# f29h85x_hsm_fri_regs register map
Vendor: Texas Instruments
Peripheral module from a debugger description file (folder HSM).
Registers are 32-bit, read-only, no defined reset value unless marked. A register's access mark holds for its fields unless they carry their own. Offsets are as the file gives them; lines under a group give offsets from that group; [hi:lo] are bit positions; {n}, {i} and the like mark numbered series; 'fields as' and 'values as' point back to an identical list; <NAME> marks a mode.

## HSM_FRI — HSM FRI Registers
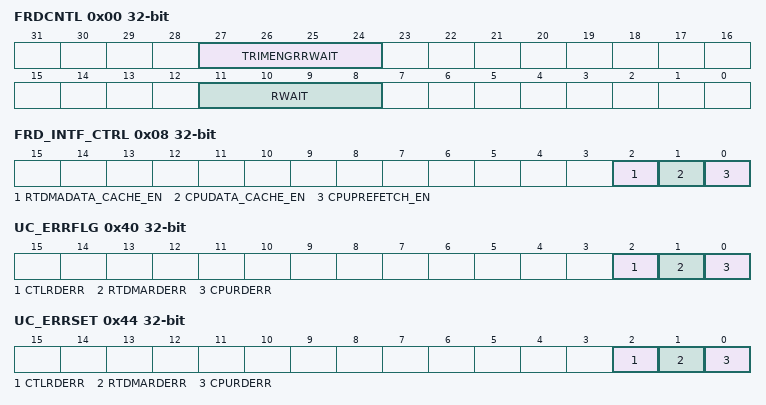
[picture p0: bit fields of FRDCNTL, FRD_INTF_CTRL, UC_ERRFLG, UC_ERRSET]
0x00 FRDCNTL access per field
  [27:24] TRIMENGRRWAIT rw, [11:8] RWAIT rw
0x04 FLCLKCTL access per field
  [3:0] KDIV rw
0x08 FRD_INTF_CTRL access per field
  [2] RTDMADATA_CACHE_EN rw, [1] CPUDATA_CACHE_EN rw, [0] CPUPREFETCH_EN rw
0x0C FLPROT access per field
  [0] FLWEPROT rw
{0x10+4i} RESERVED_1[{i}] (i=0..3)
0x20 ECC_ENABLE access per field
  [3:0] ENABLE rw
0x24 FECC_CTRL access per field
  [1:0] ECC_TEST_EN rw
{0x28+4i} RESERVED_2[{i}] (i=0..5)
0x40 UC_ERRFLG
  [2] CTLRDERR, [1] RTDMARDERR, [0] CPURDERR
0x44 UC_ERRSET access per field
  [2] CTLRDERR rw, [1] RTDMARDERR rw, [0] CPURDERR rw
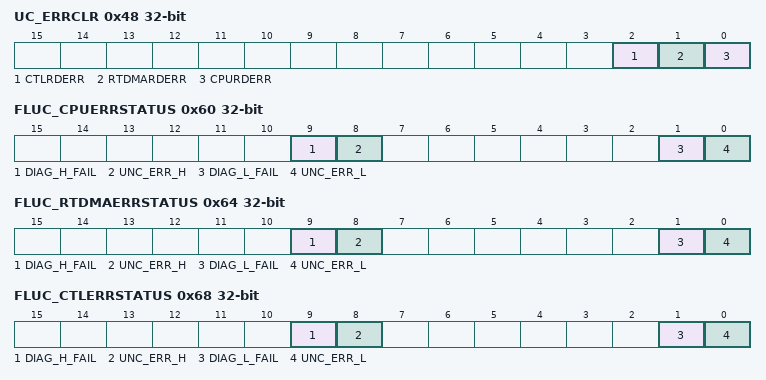
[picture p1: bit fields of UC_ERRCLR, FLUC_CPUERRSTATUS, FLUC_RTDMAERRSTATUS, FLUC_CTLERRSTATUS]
0x48 UC_ERRCLR access per field
  [2] CTLRDERR rw, [1] RTDMARDERR rw, [0] CPURDERR rw
0x4C UC_CPUREADDR
0x50 UC_RTDMAREADDR
0x54 UC_CTLREADDR
{0x58+4i} RESERVED_3[{i}] (i=0..1)
0x60 FLUC_CPUERRSTATUS
  [9] DIAG_H_FAIL, [8] UNC_ERR_H, [1] DIAG_L_FAIL, [0] UNC_ERR_L
0x64 FLUC_RTDMAERRSTATUS
  [9] DIAG_H_FAIL, [8] UNC_ERR_H, [1] DIAG_L_FAIL, [0] UNC_ERR_L
0x68 FLUC_CTLERRSTATUS
  [9] DIAG_H_FAIL, [8] UNC_ERR_H, [1] DIAG_L_FAIL, [0] UNC_ERR_L
{0x6C+4i} RESERVED_4[{i}] (i=0..4)
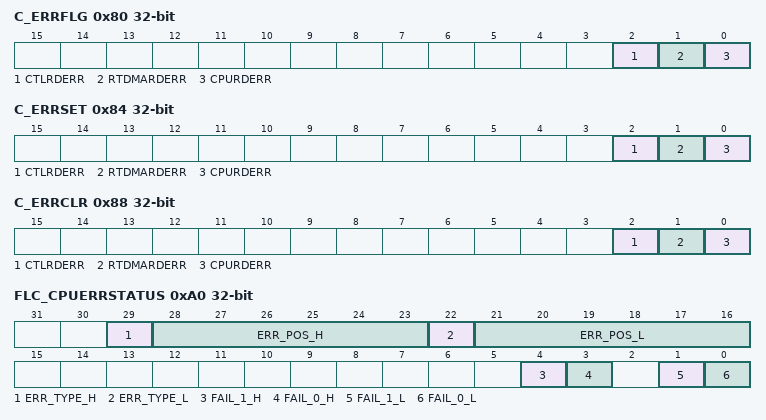
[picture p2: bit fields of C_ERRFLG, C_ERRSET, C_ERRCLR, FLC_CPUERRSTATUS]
0x80 C_ERRFLG
  [2] CTLRDERR, [1] RTDMARDERR, [0] CPURDERR
0x84 C_ERRSET access per field
  [2] CTLRDERR rw, [1] RTDMARDERR rw, [0] CPURDERR rw
0x88 C_ERRCLR access per field
  [2] CTLRDERR rw, [1] RTDMARDERR rw, [0] CPURDERR rw
0x8C C_CPUREADDR
0x90 C_RTDMAREADDR
0x94 C_CTLREADDR
{0x98+4i} RESERVED_5[{i}] (i=0..1)
0xA0 FLC_CPUERRSTATUS
  [29] ERR_TYPE_H, [28:23] ERR_POS_H, [22] ERR_TYPE_L, [21:16] ERR_POS_L, [4] FAIL_1_H, [3] FAIL_0_H, [1] FAIL_1_L, [0] FAIL_0_L
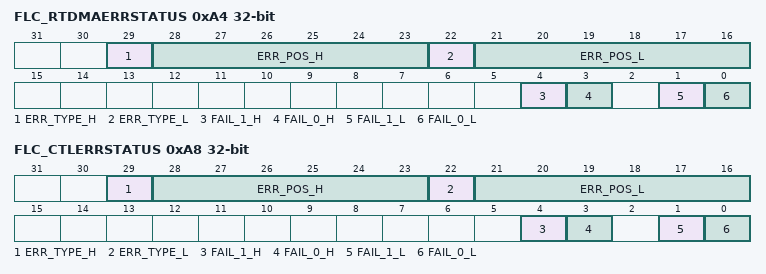
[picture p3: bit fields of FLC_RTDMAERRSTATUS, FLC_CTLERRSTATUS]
0xA4 FLC_RTDMAERRSTATUS
  fields as FLC_CPUERRSTATUS
0xA8 FLC_CTLERRSTATUS
  fields as FLC_CPUERRSTATUS
{0xAC+4i} RESERVED_6[{i}] (i=0..4)
0xC0 C_ERRCNT
0xC4 C_ERRTHRES access per field
  [15:0] C_ERRTHRES rw
0xC8 C_EINTFLG
  [0] C_EINTFLAG
0xCC C_EINTCLR access per field
  [0] C_EINTCLR rw
0xD0 C_EINTSET access per field
  [0] C_EINTSET rw
0xD4 C_EINTEN access per field
  [0] C_EINTEN rw
{0xD8+4i} RESERVED_7[{i}] (i=0..969)
